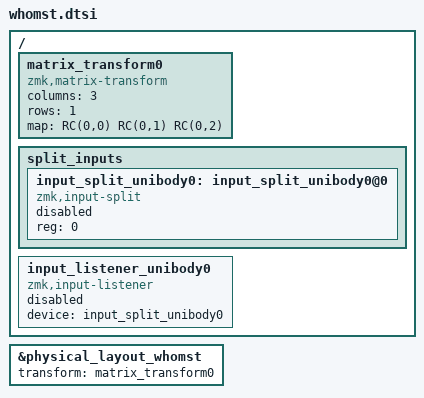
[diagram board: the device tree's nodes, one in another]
#include "whomst-layouts.dtsi"
#include <dt-bindings/zmk/matrix_transform.h>

/ {
    matrix_transform0: matrix_transform0 {
        compatible = "zmk,matrix-transform";
        columns = <3>;
        rows = <1>;
        map = <
            RC(0,0) RC(0,1) RC(0,2)
        >;
    };
};

&physical_layout_whomst {
    transform = <&matrix_transform0>;
};

// Input devices
/ {
    split_inputs {
        #address-cells = <1>;
        #size-cells = <0>;

        input_split_unibody0: input_split_unibody0@0 {
            compatible = "zmk,input-split";
            reg = <0>;
            status = "disabled";
        };
    };

    input_listener_unibody0: input_listener_unibody0 {
        compatible = "zmk,input-listener";
        status = "disabled";
        device = <&input_split_unibody0>;
    };
};

